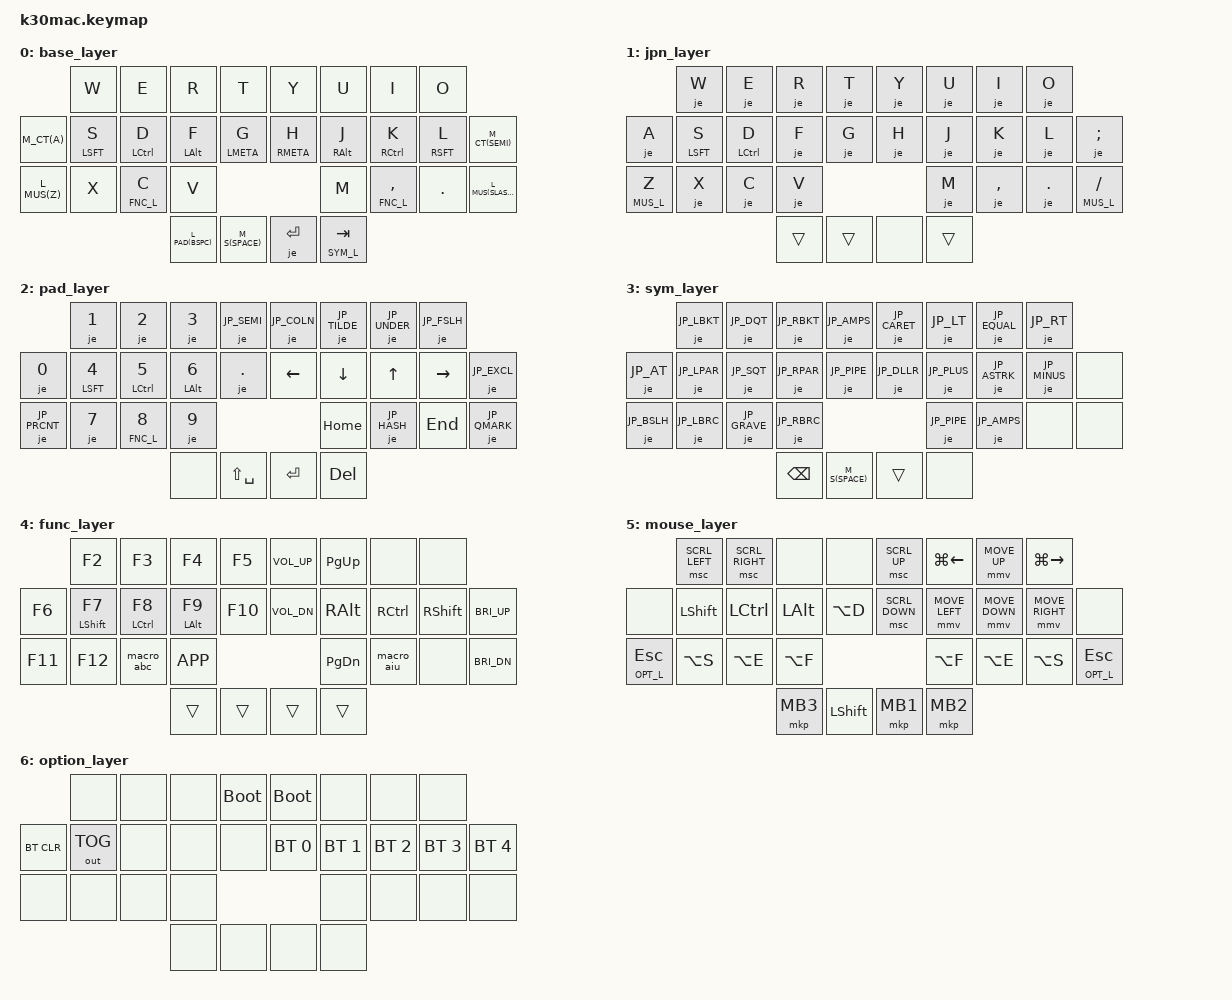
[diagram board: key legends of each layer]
/*
 * Copyright (c) 2020 The ZMK Contributors
 *
 * SPDX-License-Identifier: MIT
 */

#include <behaviors.dtsi>
#include <dt-bindings/zmk/keys.h>
#include <dt-bindings/zmk/bt.h>
#include <dt-bindings/zmk/outputs.h>
#include <dt-bindings/zmk/jp_enter.h>

#define ZMK_POINTING_DEFAULT_MOVE_VAL 2900  // default: 600
#define ZMK_POINTING_DEFAULT_SCRL_VAL 30    // default: 10
#include <dt-bindings/zmk/pointing.h>

#define BAS_L 0
#define JPN_L 1
#define PAD_L 2
#define SYM_L 3
#define FNC_L 4
#define MUS_L 5
#define OPT_L 6

#define ___ &trans
#define XXX &none

#define M_CT(k) &mt LC(LSHFT) k
#define M_S(k) &mt LSHFT k
#define L_PAD(k) &lt PAD_L k
#define L_MUS(k) &lt MUS_L k


&lt {
  flavor = "tap-preferred";
  tapping-term-ms = <180>;
  quick-tap-ms = <175>;
};
&mt {
  flavor = "tap-preferred";
  tapping-term-ms = <180>;
  quick-tap-ms = <175>;
};
&je {
  je-entry-layer = <JPN_L>;
};
&mmv {
  trigger-period-ms = <16>;
  time-to-max-speed-ms = <700>;
  acceleration-exponent = <1>;
};

/ {
  behaviors {
    jmt: my_jp_mod_tap {
      compatible = "zmk,behavior-hold-tap";
      #binding-cells = <2>;
      flavor = "tap-preferred";
      tapping-term-ms = <180>;
      quick-tap-ms = <175>;
      bindings = <&kp>, <&je>;
      display-name = "My Mod-Tap";
    };
  };
  behaviors {
    jlt: my_jp_layer_tap {
      compatible = "zmk,behavior-hold-tap";
      #binding-cells = <2>;
      flavor = "tap-preferred";
      tapping-term-ms = <180>;
      quick-tap-ms = <175>;
      bindings = <&mo>, <&je>;
      display-name = "My Layer-Tap";
    };
  };
};

/ {
  macros {
    ZMK_MACRO(macro_int5_esc,
      wait-ms = <1>;
      tap-ms = <1>;
      bindings = <&macro_abc>, <&kp ESC>;
    )
    ZMK_MACRO(macro_send_exit,
      wait-ms = <1>;
      tap-ms = <1>;
      bindings = <&kp E>, <&kp X>, <&kp I>, <&kp T>;
    )
    ZMK_MACRO(macro_abc,
      wait-ms = <1>;
      tap-ms = <1>;
      bindings = <&kp LANG2>, <&kp INT5>;
    )
    ZMK_MACRO(macro_aiu,
      wait-ms = <1>;
      tap-ms = <1>;
      bindings = <&kp LANG1>, <&kp INT4>;
    )
  };

  combos {
    compatible = "zmk,combos";

    cmb_q {
      key-positions = <0 1>;
      layers = <BAS_L>;
      bindings = <&kp Q>;
    };
    cmb_p {
      key-positions = <6 7>;
      layers = <BAS_L>;
      bindings = <&kp P>;
    };
    cmb_b {
      key-positions = <20 21>;
      layers = <BAS_L>;
      bindings = <&kp B>;
    };
    cmb_n {
      key-positions = <22 23>;
      layers = <BAS_L>;
      bindings = <&kp N>;
    };
    cmb_je_q {
      key-positions = <0 1>;
      layers = <JPN_L>;
      bindings = <&je Q>;
    };
    cmb_je_p {
      key-positions = <6 7>;
      layers = <JPN_L>;
      bindings = <&je P>;
    };
    cmb_jp_b {
      key-positions = <20 21>;
      layers = <JPN_L>;
      bindings = <&je B>;
    };
    cmb_jp_n {
      key-positions = <22 23>;
      layers = <JPN_L>;
      bindings = <&je N>;
    };

    cmb_tab {
      key-positions = <9 11>;
      layers = <BAS_L JPN_L>;
      bindings = <&kp TAB>;
    };
    cmb_enter {
      key-positions = <14 16>;
      layers = <BAS_L JPN_L>;
      bindings = <&kp ENTER>;
    };

    cmb_del {
      key-positions = <10 11>;
      layers = <BAS_L JPN_L>;
      bindings = <&kp DEL>;
    };

    cmb_yen {
      key-positions = <1 2>;
      layers = <BAS_L JPN_L>;
      bindings = <&kp JP_YEN>;
    };
    cmb_caret {
      key-positions = <4 5>;
      layers = <BAS_L JPN_L>;
      bindings = <&kp JP_CARET>;
    };
    cmb_fslh {
      key-positions = <5 6>;
      layers = <BAS_L JPN_L>;
      bindings = <&kp JP_FSLH>;
    };
    cmb_at {
      key-positions = <6 7>;
      layers = <BAS_L JPN_L>;
      bindings = <&kp JP_AT>;
    };
    cmb_bslh {
      key-positions = <23 24>;
      layers = <BAS_L JPN_L>;
      bindings = <&kp JP_BSLH>;
    };
    cmb_int5_esc {
      key-positions = <14 15>;
      layers = <BAS_L>;
      bindings = <&macro_int5_esc>;
    };
    cmb_minus {
      key-positions = <11 12>;
      layers = <BAS_L JPN_L>;
      bindings = <&kp MINUS>;
    };

    cmb_esc {
      key-positions = <14 15>;
      layers = <JPN_L>;
      bindings = <&kp ESC>;
    };

    combo_send_exit {
      key-positions = <8 19>;
      bindings = <&macro_send_exit>;
      layers = <BAS_L>;
    };

  };

  keymap {
    compatible = "zmk,keymap";
    //                |     0       |     1       |     2       |     3     |    |     4       |     5       |     6       |     7       |
    //  |     8       |     9       |    10       |    11       |    12     |    |    13       |    14       |    15       |    16       |    17     |
    //  |    18       |    19       |    20       |    21       |                              |    22       |    23       |    24       |    25     |
    //                                            |    26       |    27     |    |    28       |    29       |

    base_layer {
      bindings = <
                      &kp W         &kp E         &kp R         &kp T            &kp Y         &kp U         &kp I         &kp O
        M_CT(A)       &mt LSFT S    &mt LCTRL D   &mt LALT F    &mt LMETA G      &mt RMETA H   &mt RALT J    &mt RCTRL K   &mt RSFT L    M_CT(SEMI)
        L_MUS(Z)      &kp X         &lt FNC_L C   &kp V                                        &kp M         &lt FNC_L COMMA &kp DOT     L_MUS(SLASH)
                                                  L_PAD(BSPC)   M_S(SPACE)       &je ENTER     &lt SYM_L TAB
      >;
    };

    jpn_layer {
      bindings = <
                      &je W         &je E         &je R          &je T           &je Y         &je U         &je I         &je O
        &je A         &jmt LSFT S   &jmt LCTL D   &je F          &je G           &je H         &je J         &je K         &je L         &je SEMI
        &jlt MUS_L Z  &je X         &je C         &je V                                        &je M         &je COMMA     &je DOT       &jlt MUS_L SLASH
                                                  ___            ___             XXX           ___
      >;
    };

    pad_layer {
      bindings = <
                      &je N1        &je N2        &je N3         &je JP_SEMI     &je JP_COLN   &je JP_TILDE  &je JP_UNDER  &je JP_FSLH
        &je N0        &jmt LSFT N4  &jmt LCTRL N5 &jmt LALT N6   &je DOT         &kp LEFT      &kp DOWN      &kp UP        &kp RIGHT     &je JP_EXCL
        &je JP_PRCNT  &je N7        &jlt FNC_L N8 &je N9                                       &kp HOME      &je JP_HASH   &kp END       &je JP_QMARK
                                                  XXX            &kp LS(SPACE)   &kp ENTER     &kp DEL
      >;
    };

    sym_layer {
      bindings = <
                      &je JP_LBKT   &je JP_DQT    &je JP_RBKT   &je JP_AMPS      &je JP_CARET  &je JP_LT     &je JP_EQUAL  &je JP_RT
        &je JP_AT     &je JP_LPAR   &je JP_SQT    &je JP_RPAR   &je JP_PIPE      &je JP_DLLR   &je JP_PLUS   &je JP_ASTRK  &je JP_MINUS  &none
        &je JP_BSLH   &je JP_LBRC   &je JP_GRAVE  &je JP_RBRC                                  &je JP_PIPE   &je JP_AMPS   &none         &none
                                                  &kp BSPC      M_S(SPACE)       ___           XXX
      >;
    };

    func_layer {
      bindings = <
                      &kp F2        &kp F3        &kp F4        &kp F5           &kp C_VOL_UP  &kp PG_UP     XXX           XXX
        &kp F6        &mt LSHFT F7  &mt LCTRL F8  &mt LALT F9   &kp F10          &kp C_VOL_DN  &kp RALT      &kp RCTRL     &kp RSHFT     &kp C_BRI_UP
        &kp F11       &kp F12       &macro_abc    &kp K_APP                                    &kp PG_DN     &macro_aiu    XXX           &kp C_BRI_DN
                                                  ___           ___              ___           ___
      >;
    };

    mouse_layer {
      bindings = <
                   &msc SCRL_LEFT &msc SCRL_RIGHT XXX          XXX               &msc SCRL_UP  &kp LG(LEFT) &mmv MOVE_UP   &kp LG(RIGHT)
        XXX           &kp LSHFT     &kp LCTRL     &kp LALT     &kp LA(D)         &msc SCRL_DOWN &mmv MOVE_LEFT &mmv MOVE_DOWN &mmv MOVE_RIGHT XXX
        &lt OPT_L ESC &kp LA(S)     &kp LA(E)     &kp LA(F)                                     &kp LA(F)    &kp LA(E)      &kp LA(S)     &lt OPT_L ESC
                                                  &mkp MB3     &kp LSHFT         &mkp MB1      &mkp MB2
      >;
    };

    option_layer {
      bindings = <
                      XXX           XXX           XXX         &bootloader    &bootloader       XXX           XXX           XXX
        &bt BT_CLR    &out OUT_TOG  XXX           XXX           XXX              &bt BT_SEL 0  &bt BT_SEL 1  &bt BT_SEL 2  &bt BT_SEL 3  &bt BT_SEL 4
        XXX           XXX           XXX           XXX                                          XXX           XXX           XXX           XXX
                                                  XXX           XXX              XXX           XXX
      >;
    };

  };  // keymap

};

